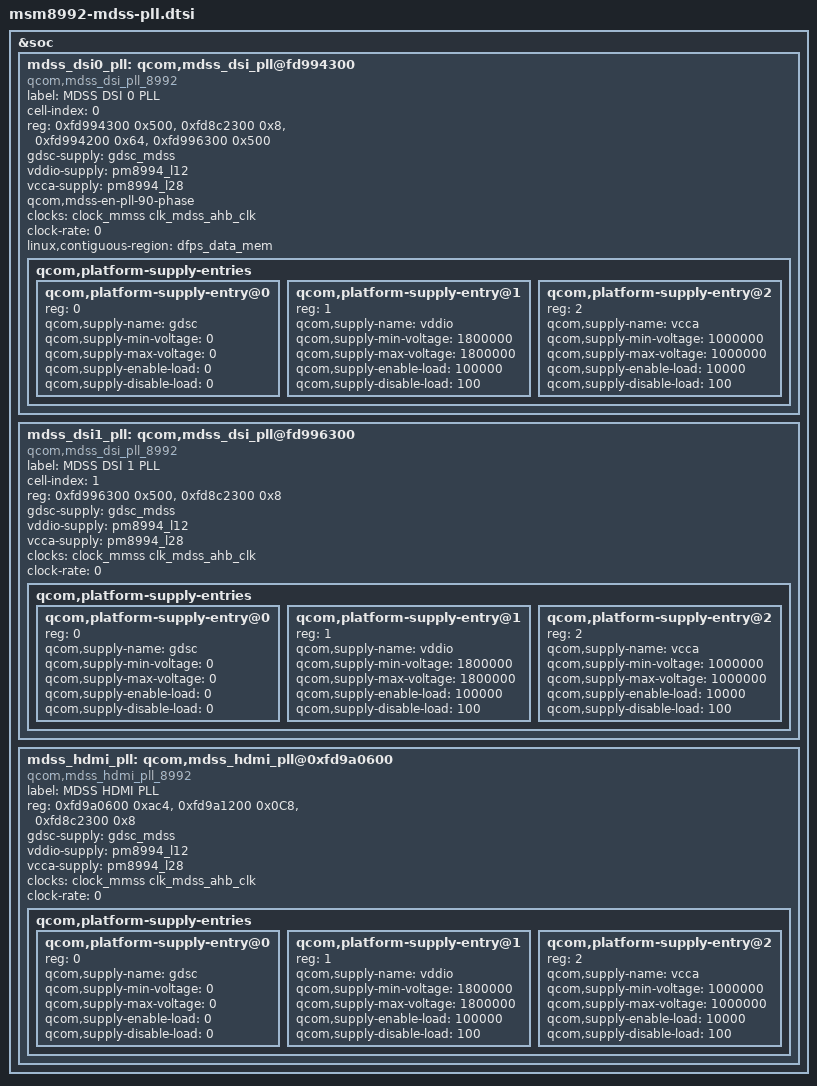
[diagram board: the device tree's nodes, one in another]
/* Copyright (c) 2014-2015, The Linux Foundation. All rights reserved.
 *
 * This program is free software; you can redistribute it and/or modify
 * it under the terms of the GNU General Public License version 2 and
 * only version 2 as published by the Free Software Foundation.
 *
 * This program is distributed in the hope that it will be useful,
 * but WITHOUT ANY WARRANTY; without even the implied warranty of
 * MERCHANTABILITY or FITNESS FOR A PARTICULAR PURPOSE.  See the
 * GNU General Public License for more details.
 */

&soc {
	mdss_dsi0_pll: qcom,mdss_dsi_pll@fd994300 {
		compatible = "qcom,mdss_dsi_pll_8992";
		label = "MDSS DSI 0 PLL";
		cell-index = <0>;
		#clock-cells = <1>;

		reg = <0xfd994300 0x500>,
		      <0xfd8c2300 0x8>,
                      <0xfd994200 0x64>,
		      <0xfd996300 0x500>;
		reg-names = "pll_base", "gdsc_base", "dynamic_pll_base",
			"pll_1_base";

		gdsc-supply = <&gdsc_mdss>;
		vddio-supply = <&pm8994_l12>;
		vcca-supply = <&pm8994_l28>;
		qcom,mdss-en-pll-90-phase;
		clocks = <&clock_mmss clk_mdss_ahb_clk>;
		clock-names = "iface_clk";
		clock-rate = <0>;

		/* Dynamic FPS data region */
		linux,contiguous-region = <&dfps_data_mem>;

		qcom,platform-supply-entries {
			#address-cells = <1>;
			#size-cells = <0>;

			qcom,platform-supply-entry@0 {
				reg = <0>;
				qcom,supply-name = "gdsc";
				qcom,supply-min-voltage = <0>;
				qcom,supply-max-voltage = <0>;
				qcom,supply-enable-load = <0>;
				qcom,supply-disable-load = <0>;
			};

			qcom,platform-supply-entry@1 {
				reg = <1>;
				qcom,supply-name = "vddio";
				qcom,supply-min-voltage = <1800000>;
				qcom,supply-max-voltage = <1800000>;
				qcom,supply-enable-load = <100000>;
				qcom,supply-disable-load = <100>;
			};

			qcom,platform-supply-entry@2 {
				reg = <2>;
				qcom,supply-name = "vcca";
				qcom,supply-min-voltage = <1000000>;
				qcom,supply-max-voltage = <1000000>;
				qcom,supply-enable-load = <10000>;
				qcom,supply-disable-load = <100>;
			};
		};
	};
	mdss_dsi1_pll: qcom,mdss_dsi_pll@fd996300 {
		compatible = "qcom,mdss_dsi_pll_8992";
		label = "MDSS DSI 1 PLL";
		cell-index = <1>;
		#clock-cells = <1>;

		reg = <0xfd996300 0x500>,
                      <0xfd8c2300 0x8>;
		reg-names = "pll_base", "gdsc_base";

		gdsc-supply = <&gdsc_mdss>;
		vddio-supply = <&pm8994_l12>;
		vcca-supply = <&pm8994_l28>;

		clocks = <&clock_mmss clk_mdss_ahb_clk>;
		clock-names = "iface_clk";
		clock-rate = <0>;

		qcom,platform-supply-entries {
			#address-cells = <1>;
			#size-cells = <0>;

			qcom,platform-supply-entry@0 {
				reg = <0>;
				qcom,supply-name = "gdsc";
				qcom,supply-min-voltage = <0>;
				qcom,supply-max-voltage = <0>;
				qcom,supply-enable-load = <0>;
				qcom,supply-disable-load = <0>;
			};

			qcom,platform-supply-entry@1 {
				reg = <1>;
				qcom,supply-name = "vddio";
				qcom,supply-min-voltage = <1800000>;
				qcom,supply-max-voltage = <1800000>;
				qcom,supply-enable-load = <100000>;
				qcom,supply-disable-load = <100>;
			};

			qcom,platform-supply-entry@2 {
				reg = <2>;
				qcom,supply-name = "vcca";
				qcom,supply-min-voltage = <1000000>;
				qcom,supply-max-voltage = <1000000>;
				qcom,supply-enable-load = <10000>;
				qcom,supply-disable-load = <100>;
			};
		};
	};

	mdss_hdmi_pll: qcom,mdss_hdmi_pll@0xfd9a0600 {
		compatible = "qcom,mdss_hdmi_pll_8992";
		label = "MDSS HDMI PLL";
		#clock-cells = <1>;

		reg = <0xfd9a0600 0xac4>,
                      <0xfd9a1200 0x0C8>,
                      <0xfd8c2300 0x8>;
		reg-names = "pll_base", "phy_base", "gdsc_base";

		gdsc-supply = <&gdsc_mdss>;
		vddio-supply = <&pm8994_l12>;
		vcca-supply = <&pm8994_l28>;

		clocks = <&clock_mmss clk_mdss_ahb_clk>;
		clock-names = "iface_clk";
		clock-rate = <0>;

		qcom,platform-supply-entries {
			#address-cells = <1>;
			#size-cells = <0>;

			qcom,platform-supply-entry@0 {
				reg = <0>;
				qcom,supply-name = "gdsc";
				qcom,supply-min-voltage = <0>;
				qcom,supply-max-voltage = <0>;
				qcom,supply-enable-load = <0>;
				qcom,supply-disable-load = <0>;
			};

			qcom,platform-supply-entry@1 {
				reg = <1>;
				qcom,supply-name = "vddio";
				qcom,supply-min-voltage = <1800000>;
				qcom,supply-max-voltage = <1800000>;
				qcom,supply-enable-load = <100000>;
				qcom,supply-disable-load = <100>;
			};

			qcom,platform-supply-entry@2 {
				reg = <2>;
				qcom,supply-name = "vcca";
				qcom,supply-min-voltage = <1000000>;
				qcom,supply-max-voltage = <1000000>;
				qcom,supply-enable-load = <10000>;
				qcom,supply-disable-load = <100>;
			};
		};
	};
};
